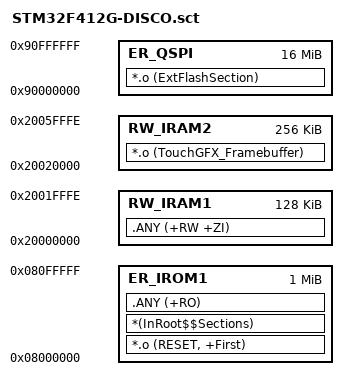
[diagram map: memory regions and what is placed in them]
; *************************************************************
; *** Scatter-Loading Description File generated by uVision ***
; *************************************************************

LR_IROM1 0x08000000 0x00100000  {    ; load region size_region
  ER_IROM1 0x08000000 0x00100000  {  ; load address = execution address
   *.o (RESET, +First)
   *(InRoot$$Sections)
   .ANY (+RO)
  }
  RW_IRAM1 0x20000000 0x0001FFFF  {  ; RW data
   .ANY (+RW +ZI)
  }
  RW_IRAM2 0x20020000 0x0003FFFF  {  ; RW data
   *.o (TouchGFX_Framebuffer)
  }
}

LR_QSPI 0x90000000 0x01000000  {    ; load region size_region
  ER_QSPI 0x90000000 0x01000000  {  ; load address = execution address
   *.o (ExtFlashSection)
;  *.o (FontFlashSection)
;  *.o (TextFlashSection)
  }
}
